# R9A09G057H register map
Vendor: Renesas Electronics; File version: 1.00
CPU: other r0p3, little endian, MPU, FPU, vendor SysTick, 4 interrupt priority bits, 480 interrupts
Registers are 32-bit, read-write, no defined reset value unless marked. A register's access mark holds for its fields unless they carry their own. Offsets are from the block's base; [hi:lo] are bit positions; lines under a group give offsets from that group; {n}, {i} and the like mark numbered series; 'fields as' and 'values as' point back to an identical list; <NAME> marks a mode.

## R_CANFD — IO define file for canfd.
Base 0x12440000
{0x0+0x10*i} CFDC[{i}] (i=0..5) group — Channel Control/Status
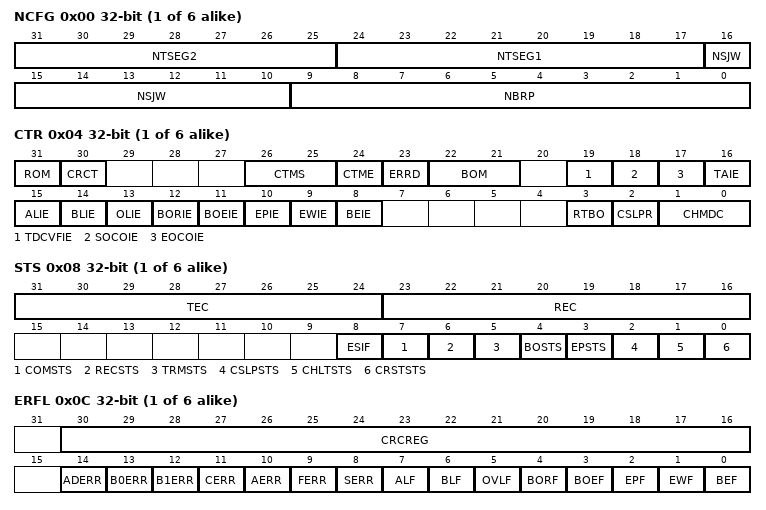
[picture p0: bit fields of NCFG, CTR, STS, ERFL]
  0x00 NCFG — Channel Nominal Bitrate Configuration Register
    [31:25] NTSEG2 — Timing Segment 2
    [24:17] NTSEG1 — Timing Segment 1
    [16:10] NSJW — Resynchronization Jump Width
    [9:0] NBRP — Channel Nominal Baud Rate Prescaler
  0x04 CTR — Channel Control Registers
    [31] ROM — Restricted Operation Mode
    [30] CRCT — CRC Error Test
    [26:25] CTMS — Channel Test Mode Select
    [24] CTME — Channel Test Mode Enable
    [23] ERRD — Channel Error Display
    [22:21] BOM — Channel Bus-Off Mode
    [19] TDCVFIE — Transceiver Delay Compensation Violation Interrupt enable
    [18] SOCOIE — Successful Occurrence Counter Overflow Interrupt enable
    [17] EOCOIE — Error occurrence counter overflow Interrupt enable
    [16] TAIE — Transmission abort Interrupt Enable
    [15] ALIE — Arbitration Lost Interrupt Enable
    [14] BLIE — Bus Lock Interrupt Enable
    [13] OLIE — Overload Interrupt Enable
    [12] BORIE — Bus-Off Recovery Interrupt Enable
    [11] BOEIE — Bus-Off Entry Interrupt Enable
    [10] EPIE — Error Passive Interrupt Enable
    [9] EWIE — Error Warning Interrupt Enable
    [8] BEIE — Bus Error Interrupt Enable
    [3] RTBO — Return from Bus-Off
    [2] CSLPR — Channel Sleep Request
    [1:0] CHMDC — Channel Mode Control
  0x08 STS — Channel Status Registers
    [31:24] TEC — Transmission Error Count
    [23:16] REC ro — Reception Error Count
    [8] ESIF — Error State Indication Flag
    [7] COMSTS ro — Channel Communication Status
    [6] RECSTS ro — Channel Receive Status
    [5] TRMSTS ro — Channel Transmit Status
    [4] BOSTS ro — Channel Bus-Off Status
    [3] EPSTS ro — Channel Error Passive Status
    [2] CSLPSTS ro — Channel SLEEP Status
    [1] CHLTSTS ro — Channel HALT Status
    [0] CRSTSTS ro — Channel RESET Status
  0x0C ERFL — Channel Error Flag Registers
    [30:16] CRCREG ro — CRC Register value
    [14] ADERR — Acknowledge Delimiter Error
    [13] B0ERR — Bit 0 Error
    [12] B1ERR — Bit 1 Error
    [11] CERR — CRC Error
    [10] AERR — Acknowledge Error
    [9] FERR — Form Error
    [8] SERR — Stuff Error
    [7] ALF — Arbitration Lost Flag
    [6] BLF — Bus Lock Flag
    [5] OVLF — Overload Flag
    [4] BORF — Bus-Off Recovery Flag
    [3] BOEF — Bus-Off Entry Flag
    [2] EPF — Error Passive Flag
    [1] EWF — Error Warning Flag
    [0] BEF — Bus Error Flag
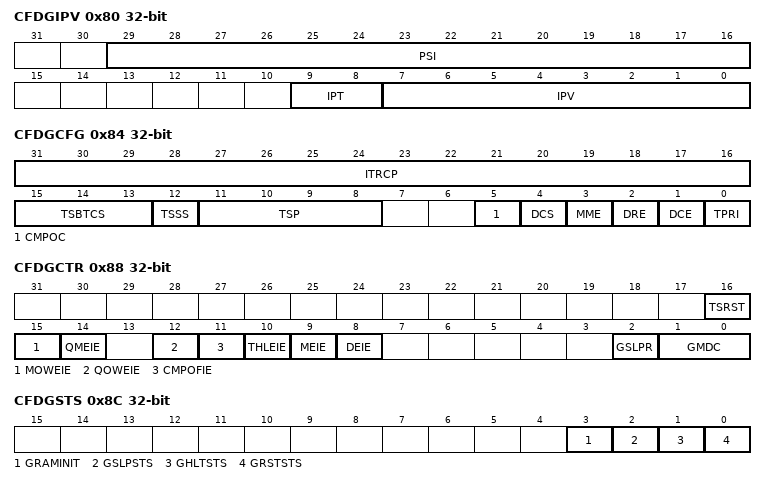
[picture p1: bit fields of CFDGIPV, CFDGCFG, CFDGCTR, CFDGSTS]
0x80 CFDGIPV ro — Global IP Version Register
  [29:16] PSI rw — Parameter Status Information
  [9:8] IPT rw — IP Type
  [7:0] IPV rw — IP Version
0x84 CFDGCFG — Global Configuration Register
  [31:16] ITRCP — Interval Timer Reference Clock Prescaler
  [15:13] TSBTCS — Timestamp Bit Time Channel Select
  [12] TSSS — Timestamp Source Select
  [11:8] TSP — Timestamp Prescaler
  [5] CMPOC — CAN-FD message Payload overflow configuration
  [4] DCS — Data Link Controller Clock Select
  [3] MME — Mirror Mode Enable
  [2] DRE — DLC Replacement Enable
  [1] DCE — DLC Check Enable
  [0] TPRI — Transmission Priority
0x88 CFDGCTR — Global Control Register
  [16] TSRST — Timestamp Reset
  [15] MOWEIE — GW FIFO Message overwrite Error Interrupt Enable
  [14] QMEIE — TXQ Message lost Error Interrupt Enable
  [12] QOWEIE — TXQ Message Overwrite Error Interrupt Enable
  [11] CMPOFIE — CAN-FD message payload overflow Flag Interrupt enable
  [10] THLEIE — TX History List Entry Lost Interrupt Enable
  [9] MEIE — Message lost Error Interrupt Enable
  [8] DEIE — DLC check Interrupt Enable
  [2] GSLPR — Global Sleep Request
  [1:0] GMDC — Global Mode Control
0x8C CFDGSTS — Global Status Register
  [3] GRAMINIT ro — Global RAM Initialisation
  [2] GSLPSTS ro — Global Sleep Status
  [1] GHLTSTS ro — Global Halt Status
  [0] GRSTSTS ro — Global Reset Status
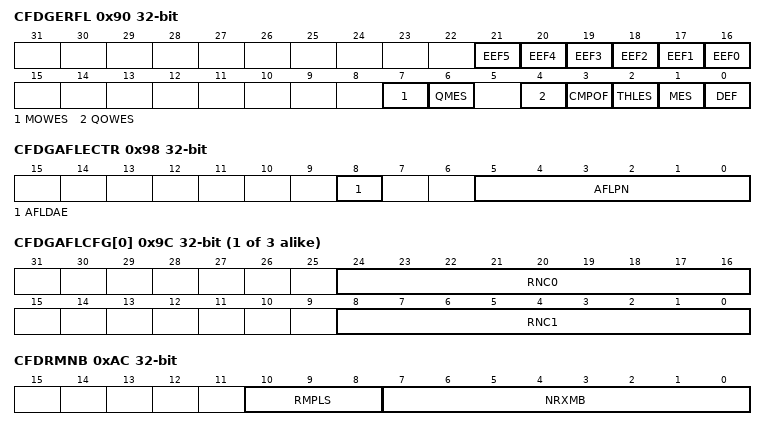
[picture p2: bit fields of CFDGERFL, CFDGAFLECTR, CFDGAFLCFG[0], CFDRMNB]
0x90 CFDGERFL — Global Error Flag Register
  [n+16] EEF{n} (n=0..5) — ECC Error Flag for Channel {n}
  [7] MOWES ro — Message Overwrite Error Status
  [6] QMES ro — TXQ Message Lost Error Status
  [4] QOWES ro — TXQ Message overwrite Error Status
  [3] CMPOF — CAN-FD message payload overflow Flag
  [2] THLES ro — TX History List Entry Lost Error Status
  [1] MES ro — Message Lost Error Status
  [0] DEF — DLC Error Flag
0x94 CFDGTSC — Global Timestamp Counter Register
  [15:0] TS ro — Timestamp Value
0x98 CFDGAFLECTR — Global Acceptance Filter List Entry Control Register
  [8] AFLDAE — Acceptance Filter List Data Access Enable
  [5:0] AFLPN — Acceptance Filter List Page Number
{0x9C+4i} CFDGAFLCFG[{i}] (i=0..2) — Global Acceptance Filter List Configuration Register
  [24:16] RNC0 — Rule Number for Channel 0
  [8:0] RNC1 — Rule Number for Channel 1
0xAC CFDRMNB — RX Message Buffer Number Register
  [10:8] RMPLS — Reception Message Buffer Payload Data Size
  [7:0] NRXMB — Number of RX Message Buffers
{0xB0+4i} CFDRMND[{i}] (i=0..2) — RX Message Buffer New Data Register
  [31:0] RMNS — RX Message Buffer New Data Status
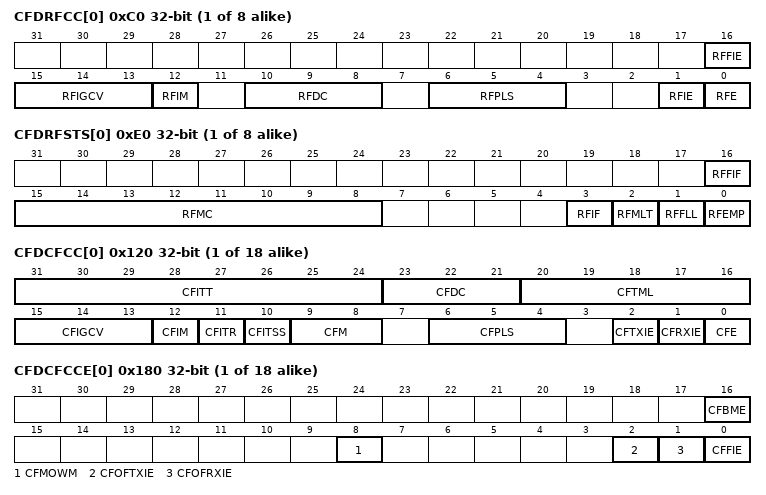
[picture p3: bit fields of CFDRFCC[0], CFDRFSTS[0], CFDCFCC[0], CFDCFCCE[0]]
{0xC0+4i} CFDRFCC[{i}] (i=0..7) — RX FIFO Configuration / Control Registers
  [16] RFFIE — RX FIFO Full interrupt Enable
  [15:13] RFIGCV — RX FIFO Interrupt Generation Counter Value
  [12] RFIM — RX FIFO Interrupt Mode
  [10:8] RFDC — RX FIFO Depth Configuration
  [6:4] RFPLS — Rx FIFO Payload Data Size configuration
  [1] RFIE — RX FIFO Interrupt Enable
  [0] RFE — RX FIFO Enable
{0xE0+4i} CFDRFSTS[{i}] (i=0..7) — RX FIFO Status Registers
  [16] RFFIF — RX FIFO Full Interrupt Flag
  [15:8] RFMC ro — RX FIFO Message Count
  [3] RFIF — RX FIFO Interrupt Flag
  [2] RFMLT — RX FIFO Message Lost
  [1] RFFLL ro — RX FIFO Full
  [0] RFEMP ro — RX FIFO Empty
{0x100+4i} CFDRFPCTR[{i}] (i=0..7) — RX FIFO Pointer Control Registers
  [7:0] RFPC wo — RX FIFO Pointer Control
{0x120+4i} CFDCFCC[{i}] (i=0..17) — Common FIFO Configuration / Control Registers
  [31:24] CFITT — Common FIFO Interval Transmission Time
  [23:21] CFDC — Common FIFO Depth Configuration
  [20:16] CFTML — Common FIFO TX Message Buffer Link
  [15:13] CFIGCV — Common FIFO Interrupt Generation Counter Value
  [12] CFIM — Common FIFO Interrupt Mode
  [11] CFITR — Common FIFO Interval Timer Resolution
  [10] CFITSS — Common FIFO Interval Timer Source Select
  [9:8] CFM — Common FIFO Mode
  [6:4] CFPLS — Common FIFO Payload Data size configuration
  [2] CFTXIE — Common FIFO TX Interrupt Enable
  [1] CFRXIE — Common FIFO RX Interrupt Enable
  [0] CFE — Common FIFO Enable
{0x180+4i} CFDCFCCE[{i}] (i=0..17) — Common FIFO Configuration / Control Enhancement Registers
  [16] CFBME — Common FIFO Buffering Mode Enable
  [8] CFMOWM — Common FIFO message overwrite mode
  [2] CFOFTXIE — Common FIFO One Frame Transmission Interrupt Enable
  [1] CFOFRXIE — Common FIFO One Frame Reception Interrupt Enable
  [0] CFFIE — Common FIFO Full interrupt Enable
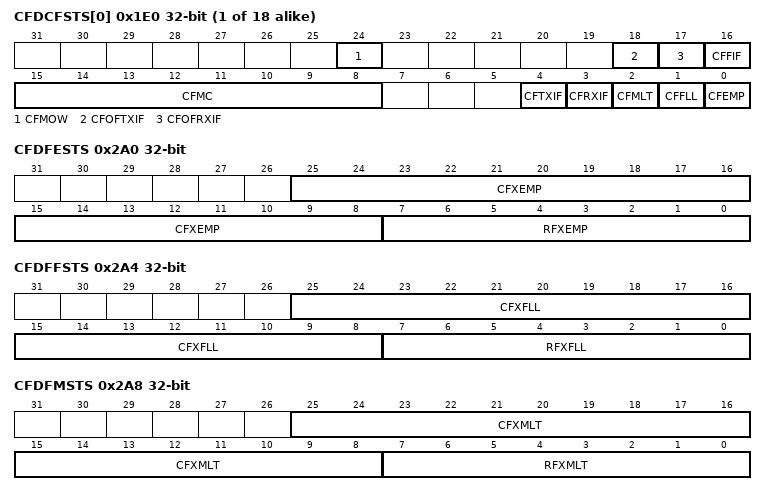
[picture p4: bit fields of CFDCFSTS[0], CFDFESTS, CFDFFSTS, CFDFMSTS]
{0x1E0+4i} CFDCFSTS[{i}] (i=0..17) — Common FIFO Status Registers
  [24] CFMOW — Common FIFO message overwrite
  [18] CFOFTXIF — Common FIFO One Frame Transmission Interrupt Flag
  [17] CFOFRXIF — Common FIFO One Frame Reception Interrupt Flag
  [16] CFFIF — Common FIFO Full Interrupt Flag
  [15:8] CFMC ro — Common FIFO Message Count
  [4] CFTXIF — Common TX FIFO Interrupt Flag
  [3] CFRXIF — Common RX FIFO Interrupt Flag
  [2] CFMLT — Common FIFO Message Lost
  [1] CFFLL ro — Common FIFO Full
  [0] CFEMP ro — Common FIFO Empty
{0x240+4i} CFDCFPCTR[{i}] (i=0..17) — Common FIFO Pointer Control Registers
  [7:0] CFPC wo — Common FIFO Pointer Control
0x2A0 CFDFESTS ro — FIFO Empty Status Register
  [25:8] CFXEMP — Common FIF0 Empty Status
  [7:0] RFXEMP — RX FIF0 Empty Status
0x2A4 CFDFFSTS ro — FIFO Full Status Register
  [25:8] CFXFLL — Common FIF0 Full Status
  [7:0] RFXFLL — RX FIF0 Full Status
0x2A8 CFDFMSTS ro — FIFO Message Lost Status Register
  [25:8] CFXMLT — Common FIFO Msg Lost Status
  [7:0] RFXMLT — RX FIFO Msg Lost Status
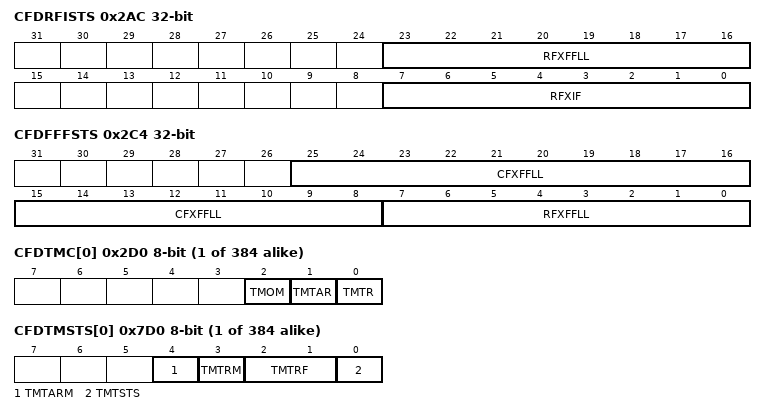
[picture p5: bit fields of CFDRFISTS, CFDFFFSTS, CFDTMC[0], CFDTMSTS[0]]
0x2AC CFDRFISTS — RX FIFO Interrupt Flag Status Register
  [23:16] RFXFFLL ro — RX FIFO[x] Interrupt Full Flag Status
  [7:0] RFXIF ro — RX FIFO[x] Interrupt Flag Status
0x2B0 CFDCFRISTS — Common FIFO RX Interrupt Flag Status Register
  [17:0] CFXRXIF ro — Common FIFO [x] RX Interrupt Flag Status
0x2B4 CFDCFTISTS — Common FIFO TX Interrupt Flag Status Register
  [17:0] CFXTXIF ro — Common FIFO [x] TX Interrupt Flag Status
0x2B8 CFDCFOFRISTS ro — Common FIFO One Frame RX Interrupt Flag Status Register
  [17:0] CFXOFRXIF — Common FIFO [x] One Frame RX Interrupt Flag Status
0x2BC CFDCFOFTISTS ro — Common FIFO One Frame TX Interrupt Flag Status Register
  [17:0] CFXOFTXIF — Common FIFO [x] One Frame TX Interrupt Flag Status
0x2C0 CFDCFMOWSTS ro — Common FIFO Message Over Write Status Register
  [17:0] CFXMOW — Common FIFO [x] Massage overwrite status
0x2C4 CFDFFFSTS ro — FIFO FDC Full Status Register
  [25:8] CFXFFLL — COMMON FIFO FDC level full Status
  [7:0] RFXFFLL — RX FIFO FDC level full Status
{0x2D0+i} CFDTMC[{i}] (i=0..383) 8-bit — TX Message Buffer Control Registers
  [2] TMOM — TX Message Buffer One-shot Mode
  [1] TMTAR — TX Message Buffer Transmission abort Request
  [0] TMTR — TX Message Buffer Transmission Request
{0x7D0+i} CFDTMSTS[{i}] (i=0..383) 8-bit — TX Message Buffer Status Registers
  [4] TMTARM ro — TX Message Buffer Transmission abort Request Mirrored
  [3] TMTRM ro — TX Message Buffer Transmission Request Mirrored
  [2:1] TMTRF — TX Message Buffer Transmission Result Flag
  [0] TMTSTS ro — TX Message Buffer Transmission Status
{0xCD0+4i} CFDTMTRSTS[{i}] (i=0..11) ro — TX Message Buffer Transmission Request Status Register
  [15:0] TMTRSTS — TX Message Buffer Transmission Request Status
{0xD70+4i} CFDTMTARSTS[{i}] (i=0..11) ro — TX Message Buffer Transmission Abort Request Status Register
  [15:0] TMTARSTS — TX Message Buffer Transmission abort Request Status
{0xE10+4i} CFDTMTCSTS[{i}] (i=0..11) ro — TX Message Buffer Transmission Completion Status Register
  [15:0] TMTCSTS — TX Message Buffer Transmission Completion Status
{0xEB0+4i} CFDTMTASTS[{i}] (i=0..11) ro — TX Message Buffer Transmission Abort Status Register
  [15:0] TMTASTS — TX Message Buffer Transmission abort Status
{0xF50+4i} CFDTMIEC[{i}] (i=0..11) — TX Message Buffer Interrupt Enable Configuration Register
  [15:0] TMIE — TX Message Buffer Interrupt Enable
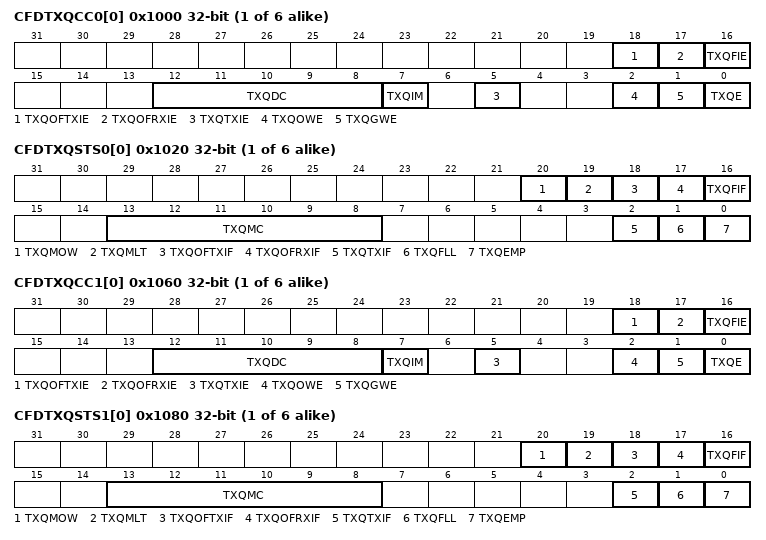
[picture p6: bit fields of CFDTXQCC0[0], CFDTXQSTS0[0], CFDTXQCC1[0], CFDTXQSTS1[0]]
{0x1000+4i} CFDTXQCC0[{i}] (i=0..5) — TX Queue Configuration / Control Registers 0
  [18] TXQOFTXIE — TXQ One Frame Transmission Interrupt Enable
  [17] TXQOFRXIE — TXQ One Frame Reception Interrupt Enable
  [16] TXQFIE — TXQ Full interrupt Enable
  [12:8] TXQDC — TX Queue Depth Configuration
  [7] TXQIM — TX Queue Interrupt Mode
  [5] TXQTXIE — TX Queue TX Interrupt Enable
  [2] TXQOWE — TX Queue Overwrite Mode Enable
  [1] TXQGWE — TX Queue Gateway Mode Enable
  [0] TXQE — TX Queue Enable
{0x1020+4i} CFDTXQSTS0[{i}] (i=0..5) — TX Queue Status Registers 0
  [20] TXQMOW — TXQ Message Overwrite
  [19] TXQMLT — TXQ Message Lost
  [18] TXQOFTXIF — TXQ One Frame Transmission Interrupt Flag
  [17] TXQOFRXIF — TXQ One Frame Reception Interrupt Flag
  [16] TXQFIF — TXQ Full Interrupt Flag
  [13:8] TXQMC ro — TX Queue Message Count
  [2] TXQTXIF — TX Queue TX Interrupt Flag
  [1] TXQFLL ro — TX Queue Full
  [0] TXQEMP ro — TX Queue Empty
{0x1040+4i} CFDTXQPCTR0[{i}] (i=0..5) — TX Queue Pointer Control Registers 0
  [7:0] TXQPC wo — TX Queue Pointer Control
{0x1060+4i} CFDTXQCC1[{i}] (i=0..5) — TX Queue Configuration / Control Registers 1
  [18] TXQOFTXIE — TXQ One Frame Transmission Interrupt Enable
  [17] TXQOFRXIE — TXQ One Frame Reception Interrupt Enable
  [16] TXQFIE — TXQ Full Interrupt Enable
  [12:8] TXQDC — TX Queue Depth Configuration
  [7] TXQIM — TX Queue Interrupt Mode
  [5] TXQTXIE — TX Queue TX Interrupt Enable
  [2] TXQOWE — TX Queue Overwrite Mode Enable
  [1] TXQGWE — TX Queue Gateway Mode Enable
  [0] TXQE — TX Queue Enable
{0x1080+4i} CFDTXQSTS1[{i}] (i=0..5) — TX Queue Status Registers 1
  fields as CFDTXQSTS0[0]
{0x10A0+4i} CFDTXQPCTR1[{i}] (i=0..5) — TX Queue Pointer Control Registers 1
  [7:0] TXQPC wo — TX Queue Pointer Control
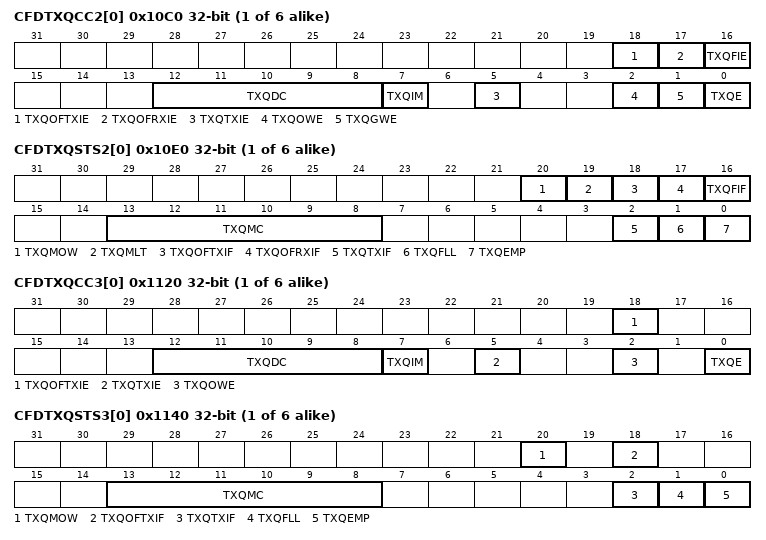
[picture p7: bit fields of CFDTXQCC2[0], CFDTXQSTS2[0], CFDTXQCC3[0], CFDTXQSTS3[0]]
{0x10C0+4i} CFDTXQCC2[{i}] (i=0..5) — TX Queue Configuration / Control Registers 2
  fields as CFDTXQCC0[0]
{0x10E0+4i} CFDTXQSTS2[{i}] (i=0..5) — TX Queue Status Registers 2
  fields as CFDTXQSTS0[0]
{0x1100+4i} CFDTXQPCTR2[{i}] (i=0..5) — TX Queue Pointer Control Registers 2
  [7:0] TXQPC wo — TX Queue Pointer Control
{0x1120+4i} CFDTXQCC3[{i}] (i=0..5) — TX Queue Configuration / Control Registers 3
  [18] TXQOFTXIE — TXQ One Frame Transmission Interrupt Enable
  [12:8] TXQDC — TX Queue Depth Configuration
  [7] TXQIM — TX Queue Interrupt Mode
  [5] TXQTXIE — TX Queue TX Interrupt Enable
  [2] TXQOWE — TX Queue Overwrite Mode Enable
  [0] TXQE — TX Queue Enable
{0x1140+4i} CFDTXQSTS3[{i}] (i=0..5) — TX Queue Status Registers 3
  [20] TXQMOW — TXQ Message Overwrite
  [18] TXQOFTXIF — TXQ One Frame Transmission Interrupt Flag
  [13:8] TXQMC ro — TX Queue Message Count
  [2] TXQTXIF — TX Queue TX Interrupt Flag
  [1] TXQFLL ro — TX Queue Full
  [0] TXQEMP ro — TX Queue Empty
{0x1160+4i} CFDTXQPCTR3[{i}] (i=0..5) — TX Queue Pointer Control Registers 3
  [7:0] TXQPC wo — TX Queue Pointer Control
0x1180 CFDTXQESTS ro — TX Queue Empty Status Register
  [23:0] TXQxEMP — TXQ empty Status
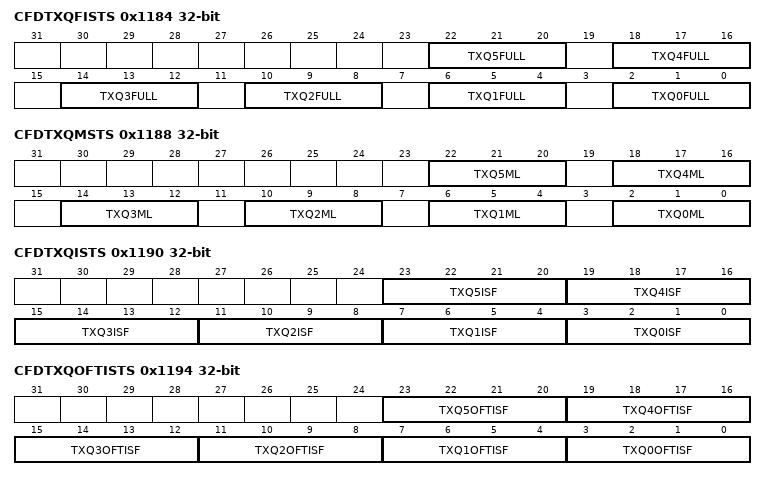
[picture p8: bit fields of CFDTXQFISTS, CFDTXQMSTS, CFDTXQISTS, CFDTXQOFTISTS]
0x1184 CFDTXQFISTS — TX Queue Full Interrupt Status Register
  [4n+2:4n] TXQ{n}FULL ro (n=0..5) — TXQ Full Interrupt Status for channel {n}
0x1188 CFDTXQMSTS — TX Queue Message Lost Status Register
  [4n+2:4n] TXQ{n}ML ro (n=0..5) — TXQ message lost Status for channel {n}
0x1190 CFDTXQISTS — TX Queue Interrupt Status Register
  [4n+3:4n] TXQ{n}ISF ro (n=0..5) — TXQ Interrupt Status Flag for channel {n}
0x1194 CFDTXQOFTISTS — TX Queue One Frame TX Interrupt Status Register
  [4n+3:4n] TXQ{n}OFTISF ro (n=0..5) — TXQ One Frame TX Interrupt Status Flag for channel {n}
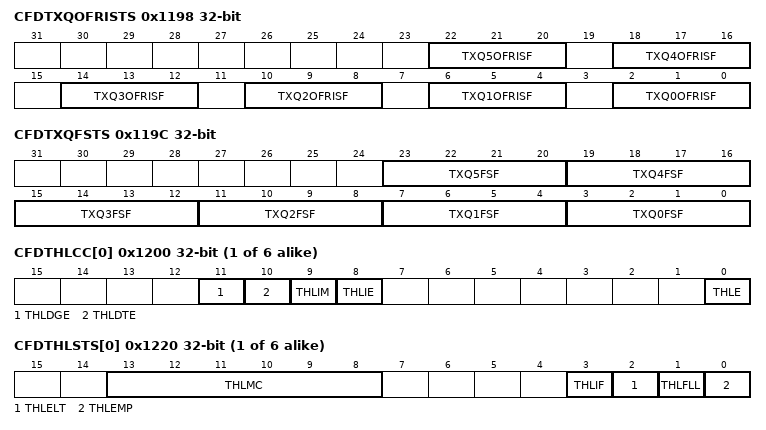
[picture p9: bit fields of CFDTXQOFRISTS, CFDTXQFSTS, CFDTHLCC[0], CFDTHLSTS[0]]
0x1198 CFDTXQOFRISTS — TX Queue One Frame RX Interrupt Status Register
  [4n+2:4n] TXQ{n}OFRISF ro (n=0..5) — TXQ One Frame RX Interrupt Status Flag for channel {n}
0x119C CFDTXQFSTS ro — TX Queue Full Status Register
  [4n+3:4n] TXQ{n}FSF (n=0..5) — TXQ Full Status Flag for channel {n}
{0x1200+4i} CFDTHLCC[{i}] (i=0..5) — TX History List Configuration / Control Register
  [11] THLDGE — TX History List Dedicated GW Enable
  [10] THLDTE — TX History List Dedicated TX Enable
  [9] THLIM — TX History List Interrupt Mode
  [8] THLIE — TX History List Interrupt Enable
  [0] THLE — TX History List Enable
{0x1220+4i} CFDTHLSTS[{i}] (i=0..5) — TX History List Status Register
  [13:8] THLMC ro — TX History List Message Count
  [3] THLIF — TX History List Interrupt Flag
  [2] THLELT — TX History List Entry Lost
  [1] THLFLL ro — TX History List Full
  [0] THLEMP ro — TX History List Empty
{0x1240+4i} CFDTHLPCTR[{i}] (i=0..5) — TX History List Pointer Control Registers
  [7:0] THLPC wo — TX History List Pointer Control
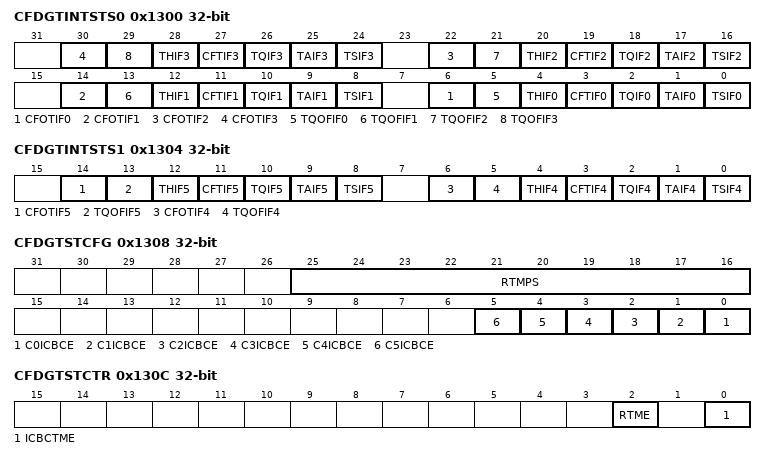
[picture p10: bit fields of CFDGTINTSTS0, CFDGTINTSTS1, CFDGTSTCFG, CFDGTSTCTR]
0x1300 CFDGTINTSTS0 — Global TX Interrupt Status Register 0
  [8n+6] CFOTIF{n} ro (n=0..3) — COM FIFO One Frame Transmission Interrupt Flag Channel {n}
  [8n+5] TQOFIF{n} ro (n=0..3) — TX Queue One Frame Transmission Interrupt Flag Channel {n}
  [8n+4] THIF{n} ro (n=0..3) — TX History List Interrupt Channel {n}
  [8n+3] CFTIF{n} ro (n=0..3) — COM FIFO TX/GW Mode Interrupt Flag Channel {n}
  [8n+2] TQIF{n} ro (n=0..3) — TX Queue Interrupt Flag Channel {n}
  [8n+1] TAIF{n} ro (n=0..3) — TX Abort Interrupt Flag Channel {n}
  [8n] TSIF{n} ro (n=0..3) — TX Successful Interrupt Flag Channel {n}
0x1304 CFDGTINTSTS1 — Global TX Interrupt Status Register 1
  [14] CFOTIF5 ro — COM FIFO One Frame Transmission Interrupt Flag Channel 5
  [13] TQOFIF5 ro — TX Queue One Frame Transmission Interrupt Flag Channel 5
  [12] THIF5 ro — TX History List Interrupt Channel 5
  [11] CFTIF5 ro — COM FIFO TX/GW Mode Interrupt Flag Channel 5
  [10] TQIF5 ro — TX Queue Interrupt Flag Channel 5
  [9] TAIF5 ro — TX Abort Interrupt Flag Channel 5
  [8] TSIF5 ro — TX Successful Interrupt Flag Channel 5
  [6] CFOTIF4 ro — COM FIFO One Frame Transmission Interrupt Flag Channel 4
  [5] TQOFIF4 ro — TX Queue One Frame Transmission Interrupt Flag Channel 4
  [4] THIF4 ro — TX History List Interrupt Channel 4
  [3] CFTIF4 ro — COM FIFO TX/GW Mode Interrupt Flag Channel 4
  [2] TQIF4 ro — TX Queue Interrupt Flag Channel 4
  [1] TAIF4 ro — TX Abort Interrupt Flag Channel 4
  [0] TSIF4 ro — TX Successful Interrupt Flag Channel 4
0x1308 CFDGTSTCFG — Global Test Configuration Register
  [25:16] RTMPS — RAM Test Mode Page Select
  [n] C{n}ICBCE (n=0..5) — Channel {n} Internal CAN Bus Communication Test Mode Enable
0x130C CFDGTSTCTR — Global Test Control Register
  [2] RTME — RAM Test Mode Enable
  [0] ICBCTME — Internal CAN Bus Communication Test Mode Enable
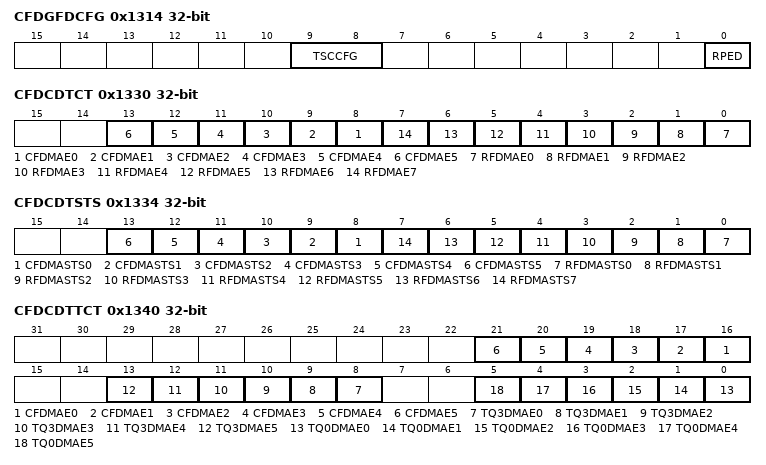
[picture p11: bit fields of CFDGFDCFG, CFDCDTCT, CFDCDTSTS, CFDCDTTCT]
0x1314 CFDGFDCFG — Global FD Configuration register
  [9:8] TSCCFG — Timestamp capture configuration
  [0] RPED — RES bit Protocol exception disable
0x131C CFDGLOCKK — Global Lock Key Register
  [15:0] LOCK wo — Lock Key
0x1330 CFDCDTCT — DMA Transfer Control Register
  [n+8] CFDMAE{n} (n=0..5) — DMA Transfer Enable for Common FIFO 0 of channel {n}
  [n] RFDMAE{n} (n=0..7) — DMA Transfer Enable for RXFIFO {n}
0x1334 CFDCDTSTS ro — DMA Transfer Status Register
  [n+8] CFDMASTS{n} (n=0..5) — DMA Transfer Status only for Common FIFO 0 of channel {n}
  [n] RFDMASTS{n} (n=0..7) — DMA Transfer Status for RX FIFO {n}
0x1340 CFDCDTTCT — DMA TX Transfer Control Register
  [n+16] CFDMAE{n} (n=0..5) — DMA TX Transfer Enable for Common FIFO 2 of channel {n}
  [n+8] TQ3DMAE{n} (n=0..5) — DMA TX Transfer Enable for TXQ 3 of channel {n}
  [n] TQ0DMAE{n} (n=0..5) — DMA TX Transfer Enable for TXQ 0 of channel {n}
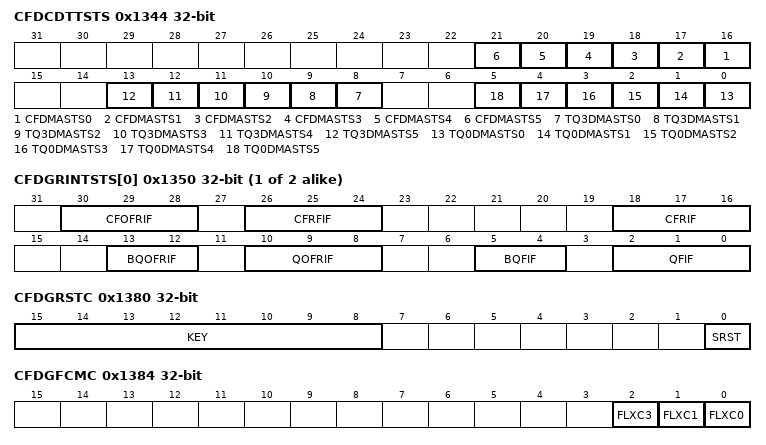
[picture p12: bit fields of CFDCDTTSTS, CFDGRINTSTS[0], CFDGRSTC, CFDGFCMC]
0x1344 CFDCDTTSTS — DMA TX Transfer Status Register
  [n+16] CFDMASTS{n} ro (n=0..5) — DMA TX Transfer Status only for Common FIFO 2 of channel {n}
  [n+8] TQ3DMASTS{n} ro (n=0..5) — DMA TX Transfer Status for TXQ3 of channel {n}
  [n] TQ0DMASTS{n} ro (n=0..5) — DMA TX Transfer Status for TXQ0 of channel {n}
{0x1350+4i} CFDGRINTSTS[{i}] (i=0..1) — Global RX Interrupt Status Register
  [30:28] CFOFRIF ro — Common FIFO One Frame RX Interrupt Flag Channel n
  [26:24] CFRFIF ro — Common FIFO FDC level Full Interrupt Flag Channel n
  [18:16] CFRIF ro — Common FIFO RX Interrupt Flag Channel n
  [13:12] BQOFRIF ro — Borrowed TXQ One Frame RX Interrupt Flag Channel n
  [10:8] QOFRIF ro — TXQ One Frame RX Interrupt Flag Channel n
  [5:4] BQFIF ro — Borrowed TXQ Full Interrupt Flag Channel n
  [2:0] QFIF ro — TXQ Full Interrupt Flag Channel n
0x1380 CFDGRSTC — Global SW reset Register
  [15:8] KEY wo — Key code
  [0] SRST — SW reset
0x1384 CFDGFCMC — Global Flexible CAN Mode Configuration Register
  [2] FLXC3 — Flexible CAN Mode between Channel 4 and Channel 5
  [1] FLXC1 — Flexible CAN Mode between Channel 2 and Channel 3
  [0] FLXC0 — Flexible CAN Mode between Channel 0 and Channel 1
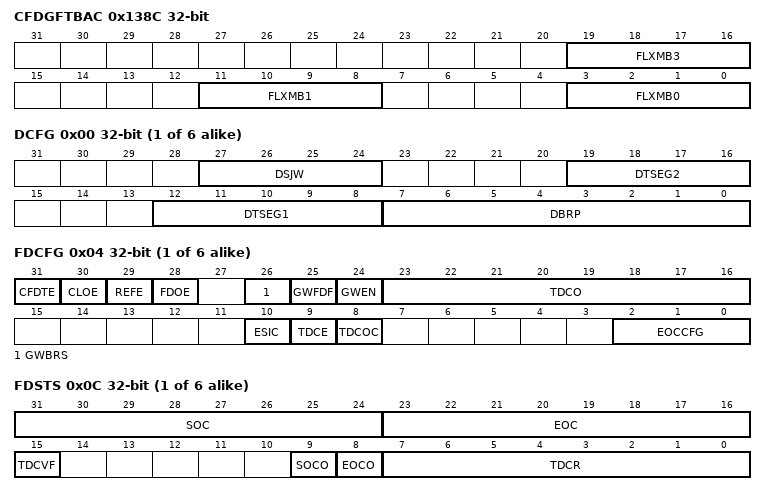
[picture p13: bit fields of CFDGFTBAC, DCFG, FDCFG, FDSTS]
0x138C CFDGFTBAC — Global Flexible Transmission Buffer Assignment Configuration Register
  [19:16] FLXMB3 — Flexible Transmission Buffer Assignment between Channel 4 and Channel 5
  [11:8] FLXMB1 — Flexible Transmission Buffer Assignment between Channel 2 and Channel 3
  [3:0] FLXMB0 — Flexible Transmission Buffer Assignment between Channel 0 and Channel 1
{0x1400+0x20*i} CFDC2[{i}] (i=0..5) group — Channel Configuration Registers
  0x00 DCFG — Channel Data Bitrate Configuration Register
    [27:24] DSJW — Resynchronization Jump Width
    [19:16] DTSEG2 — Timing Segment 2
    [12:8] DTSEG1 — Timing Segment 1
    [7:0] DBRP — Channel Data Baud Rate Prescaler
  0x04 FDCFG — Channel CAN-FD Configuration Register
    [31] CFDTE — CAN-FD Frame Distinction Enable
    [30] CLOE — Classical CAN-Only Enable
    [29] REFE — RX edge filter enable
    [28] FDOE — FD-Only Enable
    [26] GWBRS — Gateway BRS configuration bit
    [25] GWFDF — Gateway FDF configuration bit
    [24] GWEN — CAN2.0, CAN-FD <> CAN2.0, CAN-FD Multi Gateway Enable
    [23:16] TDCO — Transceiver Delay Compensation Offset
    [10] ESIC — Error State Indication Configuration
    [9] TDCE — Transceiver Delay Compensation Enable
    [8] TDCOC — Transceiver Delay Compensation Offset Configuration
    [2:0] EOCCFG — Error Occurrence Counter Configuration
  0x08 FDCTR — Channel CAN-FD Control Register
    [1] SOCCLR — Successful Occurrence Counter Clear
    [0] EOCCLR — Error Occurrence Counter Clear
  0x0C FDSTS — Channel CAN-FD Status Register
    [31:24] SOC ro — Successful occurrence counter register
    [23:16] EOC ro — Error occurrence counter register
    [15] TDCVF — Transceiver Delay Compensation Violation Flag
    [9] SOCO — Successful occurrence counter overflow
    [8] EOCO — Error occurrence counter overflow
    [7:0] TDCR ro — Transceiver Delay Compensation Result
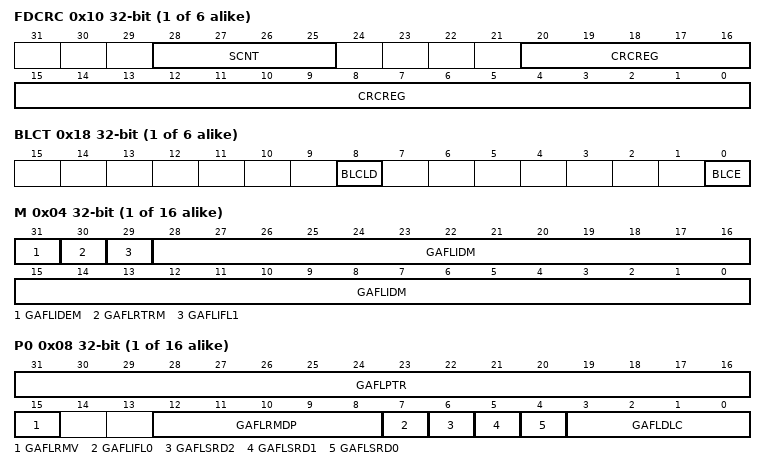
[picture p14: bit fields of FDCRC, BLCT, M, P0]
  0x10 FDCRC — Channel CAN-FD CRC Register
    [28:25] SCNT ro — Stuff bit count
    [20:0] CRCREG ro — CRC Register value
  0x18 BLCT — Channel Bus load Control Register
    [8] BLCLD wo — BUS Load counter load
    [0] BLCE — BUS Load counter Enable
  0x1C BLSTS — Channel Bus load Status Register
    [31:3] BLC ro — BUS Load counter Status
{0x1800+0x10*i} CFDGAFL[{i}] (i=0..15) group — Global Acceptance Filter List Registers
  0x00 ID — Global Acceptance Filter List ID Registers
    [31] GAFLIDE — Global Acceptance Filter List Entry IDE Field
    [30] GAFLRTR — Global Acceptance Filter List Entry RTR Field
    [29] GAFLLB — Global Acceptance Filter List Entry Loopback Configuration
    [28:0] GAFLID — Global Acceptance Filter List Entry ID Field
  0x04 M — Global Acceptance Filter List Mask Registers
    [31] GAFLIDEM — Global Acceptance Filter List IDE Mask
    [30] GAFLRTRM — Global Acceptance Filter List Entry RTR Mask
    [29] GAFLIFL1 — Global Acceptance Filter List Information Label 1
    [28:0] GAFLIDM — Global Acceptance Filter List ID Mask Field
  0x08 P0 — Global Acceptance Filter List Pointer 0 Registers
    [31:16] GAFLPTR — Global Acceptance Filter List Pointer Field
    [15] GAFLRMV — Global Acceptance Filter List RX Message Buffer Valid
    [12:8] GAFLRMDP — Global Acceptance Filter List RX Message Buffer Direction Pointer
    [7] GAFLIFL0 — Global Acceptance Filter List Information Label 0
    [6] GAFLSRD2 — Global Acceptance Filter List Select Routing destination 2
    [5] GAFLSRD1 — Global Acceptance Filter List Select Routing destination 1
    [4] GAFLSRD0 — Global Acceptance Filter List Select Routing destination 0
    [3:0] GAFLDLC — Global Acceptance Filter List DLC Field
  0x0C P1 — Global Acceptance Filter List Pointer 1 Registers
    [25:0] GAFLFDP — Global Acceptance Filter List FIFO Direction Pointer
{0x2000+0x80*i} CFDRM[{i}] (i=0..95) group — RX Message Buffer Access Registers
  0x00 ID ro — RX Message Buffer ID Register
    [31] RMIDE — RX Message Buffer IDE Bit
    [30] RMRTR — RX Message Buffer RTR Frame
    [28:0] RMID — RX Message Buffer ID Field
  0x04 PTR ro — RX Message Buffer Pointer Register
    [31:28] RMDLC — RX Message Buffer DLC Field
    [15:0] RMTS — RX Message Buffer Timestamp Field
  0x08 FDSTS ro — RX Message Buffer CAN-FD Status Register
    [31:16] RMPTR — RX Message Buffer Pointer Field
    [9:8] RMIFL — RX Message Buffer Information Label Field
    [2] RMFDF — CAN FD Format bit
    [1] RMBRS — Bit Rate Switch bit
    [0] RMESI — Error State Indicator bit
  {0xC+j} DF[{j}] (j=0..63) 8-bit ro — RX Message Buffer Data Field Registers
    [7:0] RMDB — RX Message Buffer Data Byte
{0x6000+0x80*i} CFDRF[{i}] (i=0..7) group — RX FIFO Access Registers
  0x00 ID ro — RX FIFO Access ID Register
    [31] RFIDE — RX FIFO Buffer IDE Bit
    [30] RFRTR — RX FIFO Buffer RTR Frame
    [28:0] RFID — RX FIFO Buffer ID Field
  0x04 PTR ro — RX FIFO Access Pointer Register
    [31:28] RFDLC — RX FIFO Buffer DLC Field
    [15:0] RFTS — RX FIFO Timestamp Field
  0x08 FDSTS ro — RX FIFO Access CAN-FD Status Register
    [31:16] RFPTR — RX FIFO Buffer Pointer Field
    [9:8] RFIFL — RX FIFO Buffer Information Label Field
    [2] RFFDF — CAN FD Format bit
    [1] RFBRS — Bit Rate Switch bit
    [0] RFESI — Error State Indicator bit
  {0xC+j} DF[{j}] (j=0..63) 8-bit ro — RX FIFO Access Data Field Registers
    [7:0] RFDB — RX FIFO Buffer Data Byte
{0x6400+0x80*i} CFDCF[{i}] (i=0..17) group — Common FIFO Access Registers
  0x00 ID — Common FIFO Access ID Register
    [31] CFIDE — Common FIFO Buffer IDE Bit
    [30] CFRTR — Common FIFO Buffer RTR Frame
    [29] THLEN — THL Entry Enable
    [28:0] CFID — Common FIFO Buffer ID Field
  0x04 PTR — Common FIFO Access Pointer Register
    [31:28] CFDLC — Common FIFO Buffer DLC Field
    [15:0] CFTS — Common FIFO Timestamp Field
  0x08 FDSTS — Common FIFO Access CAN-FD Status Register
    [31:16] CFPTR — Common FIFO Buffer Pointer Field
    [9:8] CFIFL — Common FIFO Buffer Information Label Field
    [2] CFFDF — CAN FD Format bit
    [1] CFBRS — Bit Rate Switch bit
    [0] CFESI — Error State Indicator bit
  {0xC+j} DF[{j}] (j=0..63) 8-bit — Common FIFO Access Data Field Registers
    [7:0] CFDB — Common FIFO Buffer Data Byte
{0x8000+8i} CFDTHL[{i}] (i=0..1) group — Channel TX History List
  0x00 ACC0 ro — Channel TX History List Access Registers 0
    [31:16] TMTS — Transmit Timestamp
    [15] TGW — Transmit Gateway Buffer indication
    [9:3] BN — Buffer No.
    [2:0] BT — Buffer Type
  0x04 ACC1 — Channel TX History List Access Registers 1
    [17:16] TIFL ro — Transmit Information Label
    [15:0] TID ro — Transmit ID
{0x8400+4i} CFDRPGACC[{i}] (i=0..63) — RAM Test Page Access Registers
  [31:0] RDTA — RAM Data Test Access
{0x10000+0x80*i} CFDTM[{i}] (i=0..383) group — TX Message Buffer Access Registers
  0x00 ID — TX Message Buffer ID Register
    [31] TMIDE — TX Message Buffer IDE Bit
    [30] TMRTR — TX Message Buffer RTR Frame
    [29] THLEN — Tx History List Entry
    [28:0] TMID — TX Message Buffer ID Field
  0x04 PTR — TX Message Buffer Pointer Register
    [31:28] TMDLC — TX Message Buffer DLC Field
  0x08 FDCTR — TX Message Buffer CAN-FD Control Register
    [31:16] TMPTR — TX Message Buffer Pointer Field
    [9:8] TMIFL — TX Message Buffer Information Label Field
    [2] TMFDF — CAN FD Format bit
    [1] TMBRS — Bit Rate Switch bit
    [0] TMESI — Error State Indicator bit
  {0xC+j} DF[{j}] (j=0..63) 8-bit — TX Message Buffer Data Field Registers
    [7:0] TMDB — TX Message Buffer Data Byte
